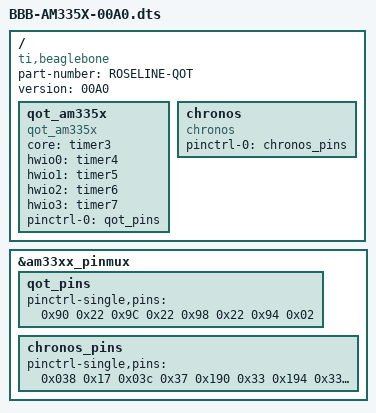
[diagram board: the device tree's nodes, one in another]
/dts-v1/;
/plugin/;
 
/ {
    /* what boards are we compatible with */
    compatible = "ti,beaglebone", "ti,beaglebone-black";
 
    /* identification */
    part-number = "ROSELINE-QOT";
 
    /* special version ignores EEPROM */
    version = "00A0";
 
    /* pin multiplexing */
    fragment@0 {
        target = <&am33xx_pinmux>;
        __overlay__ {
            qot_pins: qot_pins {
                pinctrl-single,pins = <
                    0x90  0x22      /* P8.7   MODE2 TIMER4 - CAPTURE */
                    0x9C  0x22      /* P8.9   MODE2 TIMER5 - CAPTURE */
                    0x98  0x22      /* P8.10  MODE2 TIMER6 - CAPTURE */
                    0x94  0x02      /* P8.8   MODE2 TIMER7 - CAPTURE */
                >;
            };
            chronos_pins: chronos_pins {
                pinctrl-single,pins = <
                    0x038 0x17      /* RESET P8.16 O_PULLUP | MODE7-GPIO1[14] */
                    0x03c 0x37      /* IRQ P8.15 I_PULLUP | MODE7-GPIO1[15] */
                    0x190 0x33      /* P9.31 CLK INPUT_PULLUP | MODE3 */
                    0x194 0x33      /* P9.29 MISO INPUT_PULLUP | MODE3 */
                    0x198 0x13      /* P9.30 MOSI OUTPUT_PULLUP | MODE3 */
                    0x19c 0x13      /* P9.28 CS0  OUTPUT_PULLUP | MODE3 */
                >;
            };
        };
    };
 
    /* define the basic driverset for pinmuxing timers and initializing the qot kernel */
    fragment@1 {
        target-path="/";
        __overlay__ {
            qot_am335x {
                compatible = "qot_am335x";
                status = "okay";
                core  = <&timer3>;
                hwio0 = <&timer4>;
                hwio1 = <&timer5>;
                hwio2 = <&timer6>;
                hwio3 = <&timer7>;
                pinctrl-names = "default";
                pinctrl-0 = <&qot_pins>;
            };
            chronos {
                compatible = "chronos";
                status = "okay";
                pinctrl-names = "default";
                pinctrl-0 = <&chronos_pins>;
            };
        };
    };
};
